# RX64M_CAN_Pilot register map
File version: 1.0
RX64M_CAN_Pilot peripheral registers generated from iodefine.h (pilot).
Registers are 8-bit, read-write, no defined reset value unless marked. A register's access mark holds for its fields unless they carry their own. Offsets are from the block's base; lines under a group give offsets from that group; [hi:lo] are bit positions; {n}, {i} and the like mark numbered series; 'fields as' and 'values as' point back to an identical list; <NAME> marks a mode.

## Memory map
0x00090200 CAN0 size 0x659
0x00091200 CAN1 size 0x659
0x00092200 CAN2 size 0x659

## CAN0
Base 0x00090200
Same registers: CAN1 0x00091200, CAN2 0x00092200
{0x0+0x10*i} MB{i} (i=0..31) group — MB register cluster, 32 elements.
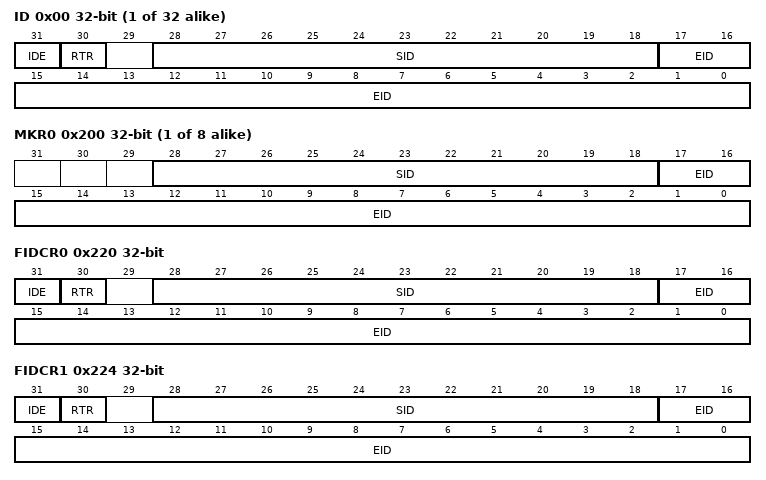
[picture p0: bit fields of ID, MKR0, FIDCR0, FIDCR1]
  0x00 ID 32-bit
    [31] IDE, [30] RTR, [28:18] SID, [17:0] EID
  0x04 DLC 16-bit
  {0x6+j} DATA{j} (j=0..7)
  0x0E TS 16-bit
{0x200+4i} MKR{i} (i=0..7) 32-bit
  [28:18] SID, [17:0] EID
0x220 FIDCR0 32-bit
  [31] IDE, [30] RTR, [28:18] SID, [17:0] EID
0x224 FIDCR1 32-bit
  [31] IDE, [30] RTR, [28:18] SID, [17:0] EID
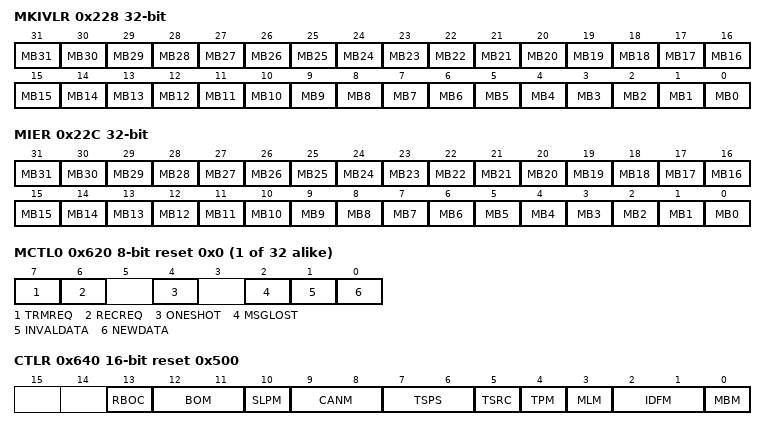
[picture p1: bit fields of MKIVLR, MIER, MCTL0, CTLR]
0x228 MKIVLR 32-bit
  [n] MB{n} (n=0..31)
0x22C MIER 32-bit
  [n] MB{n} (n=0..31)
{0x620+i} MCTL{i} (i=0..31) reset 0x0
  [7] TRMREQ, [6] RECREQ, [4] ONESHOT, [2] MSGLOST, [1] INVALDATA, [0] NEWDATA
0x640 CTLR 16-bit reset 0x500
  [13] RBOC, [12:11] BOM, [10] SLPM, [9:8] CANM, [7:6] TSPS, [5] TSRC, [4] TPM, [3] MLM, [2:1] IDFM, [0] MBM
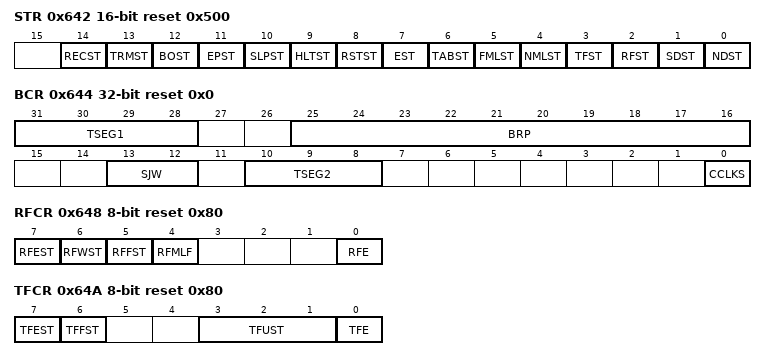
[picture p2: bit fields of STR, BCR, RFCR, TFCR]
0x642 STR 16-bit ro reset 0x500
  [14] RECST, [13] TRMST, [12] BOST, [11] EPST, [10] SLPST, [9] HLTST, [8] RSTST, [7] EST, [6] TABST, [5] FMLST, [4] NMLST, [3] TFST, [2] RFST, [1] SDST, [0] NDST
0x644 BCR 32-bit reset 0x0
  [31:28] TSEG1, [25:16] BRP, [13:12] SJW, [10:8] TSEG2, [0] CCLKS
0x648 RFCR reset 0x80
  [7] RFEST, [6] RFWST, [5] RFFST, [4] RFMLF, [0] RFE
0x649 RFPCR wo
0x64A TFCR reset 0x80
  [7] TFEST, [6] TFFST, [3:1] TFUST, [0] TFE
0x64B TFPCR wo
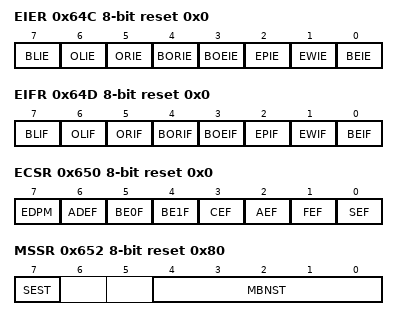
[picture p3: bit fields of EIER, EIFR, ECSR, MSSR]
0x64C EIER reset 0x0
  [7] BLIE, [6] OLIE, [5] ORIE, [4] BORIE, [3] BOEIE, [2] EPIE, [1] EWIE, [0] BEIE
0x64D EIFR reset 0x0
  [7] BLIF, [6] OLIF, [5] ORIF, [4] BORIF, [3] BOEIF, [2] EPIF, [1] EWIF, [0] BEIF
0x64E RECR ro reset 0x0
0x64F TECR ro reset 0x0
0x650 ECSR reset 0x0
  [7] EDPM, [6] ADEF, [5] BE0F, [4] BE1F, [3] CEF, [2] AEF, [1] FEF, [0] SEF
0x651 CSSR
0x652 MSSR reset 0x80
  [7] SEST, [4:0] MBNST
0x653 MSMR reset 0x0
  [1:0] MBSM
0x654 TSR 16-bit ro reset 0x0
0x656 AFSR 16-bit
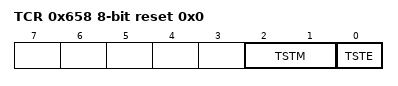
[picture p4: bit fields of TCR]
0x658 TCR reset 0x0
  [2:1] TSTM, [0] TSTE
